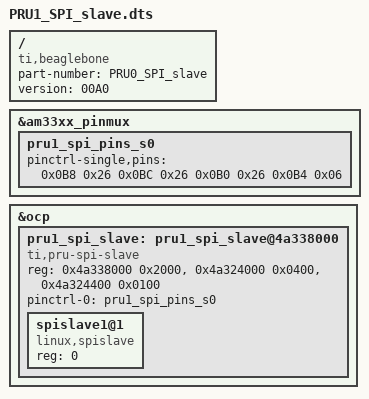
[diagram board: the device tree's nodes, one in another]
/*
 * copyright (c) 2016 patryk mezydlo <pmezydlo - mezydlo.p@gmail.com>
 *
 * this program is free software; you can redistribute it and/or modify it
 * under the terms of the gnu general public license version 2 as published by
 * the free software foundation.
 */

/dts-v1/;
/plugin/;

/{
    compatible = "ti,beaglebone", "ti,beaglebone-black";
    part-number = "PRU0_SPI_slave";
    version = "00A0";

    fragment@0 {
        target = <&am33xx_pinmux>;
        __overlay__ {
            pru1_spi_pins_s0: pru1_spi_pins_s0 {
                pinctrl-single,pins = <
                  0x0B8 0x26  /* pru0_spi_sclk, P8_39 */
                  0x0BC 0x26  /* pru0_spi_cs,   P8_40 */
                  0x0B0 0x26  /* pru0_spi_mosi, P8_41 */
                  0x0B4 0x06  /* pru0_spi_miso, P8_42 */
                >;
            };
        };
    };

    fragment@1 {
        target = <&ocp>;
        __overlay__ {
            #address-cells = <1>;
            #size-cells = <1>;

            pru1_spi_slave: pru1_spi_slave@4a338000 {
                compatible = "ti,pru-spi-slave";
                #address-cells = <1>;
                #size-cells = <0>;
		reg = <0x4a338000 0x2000>,
		      <0x4a324000 0x0400>,
		      <0x4a324400 0x0100>;
		reg-names = "iram", "control", "debug";
                status = "okay";
                pinctrl-names = "default";
                pinctrl-0 = <&pru1_spi_pins_s0>;
                spislave1@1 {
                    reg = <0>;
                    compatible = "linux,spislave";
                };
            };
        };
    };
};
